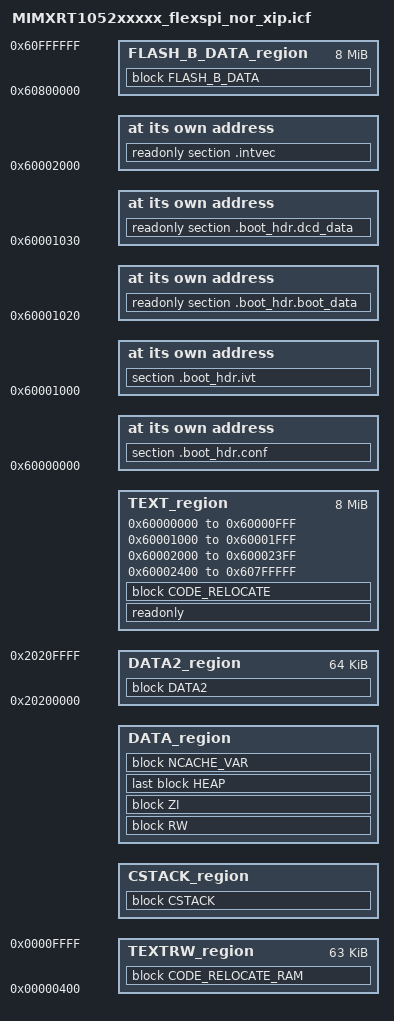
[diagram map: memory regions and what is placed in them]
/*
** ###################################################################
**     Processors:          MIMXRT1052CVL5A
**                          MIMXRT1052DVL6A
**
**     Compiler:            IAR ANSI C/C++ Compiler for ARM
**     Reference manual:    IMXRT1050RM Rev.C, 08/2017
**     Version:             rev. 0.1, 2017-01-10
**     Build:               b171208
**
**     Abstract:
**         Linker file for the IAR ANSI C/C++ Compiler for ARM
**
**     The Clear BSD License
**     Copyright 2016 Freescale Semiconductor, Inc.
**     Copyright 2016-2017 NXP
**     All rights reserved.
**
**     Redistribution and use in source and binary forms, with or without
**     modification, are permitted (subject to the limitations in the
**     disclaimer below) provided that the following conditions are met:
**
**     * Redistributions of source code must retain the above copyright
**       notice, this list of conditions and the following disclaimer.
**
**     * Redistributions in binary form must reproduce the above copyright
**       notice, this list of conditions and the following disclaimer in the
**       documentation and/or other materials provided with the distribution.
**
**     * Neither the name of the copyright holder nor the names of its
**       contributors may be used to endorse or promote products derived from
**       this software without specific prior written permission.
**
**     NO EXPRESS OR IMPLIED LICENSES TO ANY PARTY'S PATENT RIGHTS ARE
**     GRANTED BY THIS LICENSE. THIS SOFTWARE IS PROVIDED BY THE COPYRIGHT
**     HOLDERS AND CONTRIBUTORS "AS IS" AND ANY EXPRESS OR IMPLIED
**     WARRANTIES, INCLUDING, BUT NOT LIMITED TO, THE IMPLIED WARRANTIES OF
**     MERCHANTABILITY AND FITNESS FOR A PARTICULAR PURPOSE ARE
**     DISCLAIMED. IN NO EVENT SHALL THE COPYRIGHT HOLDER OR CONTRIBUTORS BE
**     LIABLE FOR ANY DIRECT, INDIRECT, INCIDENTAL, SPECIAL, EXEMPLARY, OR
**     CONSEQUENTIAL DAMAGES (INCLUDING, BUT NOT LIMITED TO, PROCUREMENT OF
**     SUBSTITUTE GOODS OR SERVICES; LOSS OF USE, DATA, OR PROFITS; OR
**     BUSINESS INTERRUPTION) HOWEVER CAUSED AND ON ANY THEORY OF LIABILITY,
**     WHETHER IN CONTRACT, STRICT LIABILITY, OR TORT (INCLUDING NEGLIGENCE
**     OR OTHERWISE) ARISING IN ANY WAY OUT OF THE USE OF THIS SOFTWARE, EVEN
**     IF ADVISED OF THE POSSIBILITY OF SUCH DAMAGE.
**
**     http:                 www.nxp.com
**     mail:                 support@nxp.com
**
** ###################################################################
*/

define symbol m_flash_config_start     = 0x60000000;
define symbol m_flash_config_end       = 0x60000FFF;

define symbol m_ivt_start              = 0x60001000;
define symbol m_ivt_end                = 0x60001FFF;

define symbol m_interrupts_start       = 0x60002000;
define symbol m_interrupts_end         = 0x600023FF;

define symbol m_text_start             = 0x60002400;
define symbol m_text_end               = 0x607FFFFF;

define symbol m_flash_b_data_start     = 0x60800000;
define symbol m_flash_b_data_end       = 0x60FFFFFF;

define symbol m_interrupts_ram_start   = 0x00000000;
define symbol m_interrupts_ram_end     = 0x000003FF;

define symbol m_textrw_start           = 0x00000400;
define symbol m_textrw_end             = 0x0000FFFF; // 64k ITCM should fit our needs

define symbol m_data_start             = 0x20000000;
define symbol m_data_end               = 0x2005FFFF; // 512k - 64k - 64k = 384k of DTCM available

define symbol m_data2_start            = 0x20200000;
define symbol m_data2_end              = 0x2020FFFF; // 64k OCRAM should be enought

define exported symbol m_boot_hdr_conf_start = 0x60000000;
define symbol m_boot_hdr_ivt_start           = 0x60001000;
define symbol m_boot_hdr_boot_data_start     = 0x60001020;
define symbol m_boot_hdr_dcd_data_start      = 0x60001030;

/* Sizes */
if (isdefinedsymbol(__stack_size__)) {
  define symbol __size_cstack__        = __stack_size__;
} else {
  define symbol __size_cstack__        = (8*1024);
}

if (isdefinedsymbol(__heap_size__)) {
  define symbol __size_heap__          = __heap_size__;
} else {
  define symbol __size_heap__          = (64*1024);
}

define exported symbol __VECTOR_TABLE  = m_interrupts_start;
define exported symbol __VECTOR_RAM    = m_interrupts_ram_start;
define exported symbol __RAM_VECTOR_TABLE_SIZE = 0x400;

define memory mem with size = 4G;
define region TEXT_region = mem:[from m_flash_config_start to m_flash_config_end]
                          | mem:[from m_ivt_start to m_ivt_end]
                          | mem:[from m_interrupts_start to m_interrupts_end]
                          | mem:[from m_text_start to m_text_end];
define region FLASH_B_DATA_region = mem:[from m_flash_b_data_start to m_flash_b_data_end];                          
define region TEXTRW_region = mem:[from m_textrw_start to m_textrw_end];
define region CSTACK_region = mem:[from m_data_start to m_data_start+__size_cstack__-1];
define region DATA_region = mem:[from m_data_start+__size_cstack__ to m_data_end];
define region DATA2_region = mem:[from m_data2_start to m_data2_end];

define block CSTACK    with alignment = 8, size = __size_cstack__   { };
define block HEAP      with alignment = 8, size = __size_heap__     { };
define block RW        { readwrite };
define block ZI        { zi };
define block DATA2      { section .ocram_data };
define block NCACHE_VAR    { section NonCacheable , section NonCacheable.init };

initialize by copy { readwrite };
do not initialize  { section .noinit };
initialize by copy { section .textrw };
initialize by copy { section .text object board.o};
define block CODE_RELOCATE  { section .textrw_init};
define block CODE_RELOCATE_RAM  { section .textrw};                           
define block FLASH_B_DATA        { section .flash_b_data };                              

place at address mem:m_boot_hdr_conf_start { section .boot_hdr.conf };
place at address mem:m_boot_hdr_ivt_start { section .boot_hdr.ivt };
place at address mem:m_boot_hdr_boot_data_start { readonly section .boot_hdr.boot_data };
place at address mem:m_boot_hdr_dcd_data_start { readonly section .boot_hdr.dcd_data };

keep{ section .boot_hdr.conf, section .boot_hdr.ivt, section .boot_hdr.boot_data, section .boot_hdr.dcd_data };

place at address mem: m_interrupts_start    { readonly section .intvec };

place in TEXT_region                        { readonly, block CODE_RELOCATE };
place in FLASH_B_DATA_region                { block FLASH_B_DATA };
place in TEXTRW_region                      { block CODE_RELOCATE_RAM };
place in DATA_region                        { block RW };
place in DATA_region                        { block ZI };
place in DATA_region                        { last block HEAP };
place in DATA_region                        { block NCACHE_VAR };
place in DATA2_region                       { block DATA2 };
place in CSTACK_region                      { block CSTACK };

